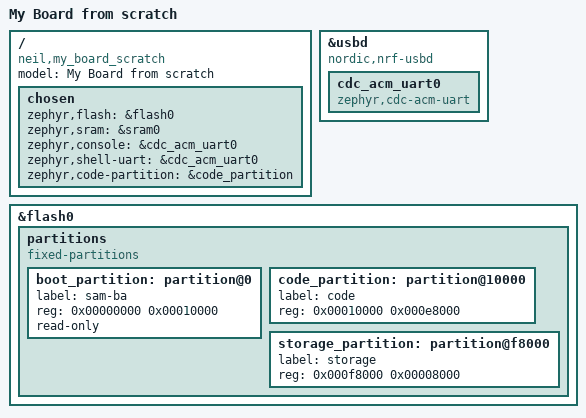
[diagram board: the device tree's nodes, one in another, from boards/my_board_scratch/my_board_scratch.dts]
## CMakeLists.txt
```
# SPDX-License-Identifier: Apache-2.0

cmake_minimum_required(VERSION 3.20.0)
list(APPEND BOARD_ROOT ${CMAKE_CURRENT_SOURCE_DIR})
find_package(Zephyr REQUIRED HINTS $ENV{ZEPHYR_BASE})
project(hello_world_scratch)

target_sources(app PRIVATE src/main.cpp)
```

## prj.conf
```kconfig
#CONFIG_CPP=y
#CONFIG_REQUIRES_FULL_LIBCPP=y
#CONFIG_GPIO=y
#CONFIG_CONSOLE=y
CONFIG_USB_DEVICE_STACK=y
#CONFIG_LOG=y
#CONFIG_PRINTK=y
#CONFIG_BOARD_EARLY_INIT_HOOK=y
CONFIG_USB_DEVICE_INITIALIZE_AT_BOOT=y
#CONFIG_UART_CONSOLE=y
#CONFIG_SERIAL=y
CONFIG_USB_CDC_ACM=y
CONFIG_UART_LINE_CTRL=y
#CONFIG_BOOT_DELAY=2000


## Preparing a separate prj.conf content for L6 onwards
```

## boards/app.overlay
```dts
/* ----practicing with aliases---------------

/{
    aliases{
        my-red-led = &red_led;
    };
};

*/
//--------------------------Homework L4 task 1----------------------------------------------------------

/{
    aliases{
        app-led = &led2; //alias app_led pointing to blue LED, i.e., 
                        // &led2 GPIO0 pin 6 on the nano33 board
    };
};
    
```

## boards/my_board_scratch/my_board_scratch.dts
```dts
/dts-v1/;
#include <nordic/nrf52840_qiaa.dtsi>
//#include <dt-bindings/gpio/gpio.h>
//#include <zephyr/dt-bindings/pinctrl/nrf-pinctrl.h>
/{
    model= "My Board from scratch";
    compatible = "neil,my_board_scratch";

    chosen{
		zephyr,flash = &flash0;
		zephyr,sram = &sram0;
		zephyr,console = &cdc_acm_uart0;
		zephyr,shell-uart = &cdc_acm_uart0;
        zephyr,code-partition = &code_partition;
    };
    
    /*aliases {
		led0 = &led0;
		led1 = &led1;
		led2 = &led2;
		led3 = &led3;
		//led4 = &led4;
	};*/

    //zephyr,user {
	//	/* I2C pull-ups are connected to VDD via pin voltage level */
	//	pull-up-gpios = <&gpio1 0 GPIO_ACTIVE_HIGH>;
	//};
    
    //leds{
    //    compatible = "gpio-leds";
	//    led0: led_0 {
	//        gpios = <&gpio0 24 GPIO_ACTIVE_LOW>;
	//        label = "Red LED";
    //    };

	//    led1: led_1 {
    //	    gpios = <&gpio0 16 GPIO_ACTIVE_LOW>;
	//	    label = "Green LED";
	//    };

	//    led2: led_2 {
	//	    gpios = <&gpio0 6 GPIO_ACTIVE_LOW>;
	//	    label = "Blue LED";
	//    };

	//    led3: led_3 {
	//        /* Cannot be used together with spi2. */
	//	    gpios = <&gpio0 13 GPIO_ACTIVE_HIGH>;
	//	    label = "Yellow LED";
	//    };
    

	    //led4: led_4 {
    	//	gpios = <&gpio1 9 GPIO_ACTIVE_HIGH>;
		//    label = "User LED";
	    //};
    //};
    
};
    
//&gpio0 {
//    status = "okay";
//};

//&gpio1 {
//	status = "okay";
//};

//&gpiote {
//	status = "okay";
//};

   
//zephyr_udc0: &usbd {
&usbd {
    compatible = "nordic,nrf-usbd";
    status = "okay";
    cdc_acm_uart0: cdc_acm_uart0 {
        compatible = "zephyr,cdc-acm-uart";
    };
};
/*
&zephyr_udc0: &usbd {
    cdc_acm_uart0: cdc_acm_uart0 {
        compatible = "zephyr,cdc-acm-uart";
    };
};*/

/*&uart0 {
    compatible = "nordic,nrf-uarte";
    current-speed = <115200>;
    status = "okay";
    pinctrl-0 = <&uart0_default>;
    pinctrl-1 = <&uart0_sleep>;
    pinctrl-names = "default", "sleep";
};
*/
&flash0 {
    partitions {
        compatible = "fixed-partitions";
        #address-cells = <1>;
        #size-cells = <1>;

        boot_partition: partition@0 {
            label = "sam-ba";
            reg = <0x00000000 0x00010000>;
            read-only;
        };

        code_partition: partition@10000 {
            label = "code";
            reg = <0x00010000 0x000e8000>;
        };
       /*
        * The flash starting at 0x000f8000 and ending at
        * 0x000fffff is reserved for use by the application.
        * Storage partition will be used by FCB/LittleFS/NVS
        * if enabled.
        */
        storage_partition: partition@f8000 {
            label = "storage";
            reg = <0x000f8000 0x00008000>;
        };
	};
};
```

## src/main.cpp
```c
/*
 * Copyright (c) 2023, Meta
 *
 * SPDX-License-Identifier: Apache-2.0
 */

#include <zephyr/kernel.h>
//#include <zephyr/usb/usb_device.h>
//#include <zephyr/drivers/uart.h>
int main(void)
{
 
   //const struct device *console = DEVICE_DT_GET(DT_CHOSEN(zephyr_console));
   //if (!device_is_ready(console)) {
    //    return -ENODEV;
    //}  
   //if (usb_enable(NULL) != 0) {
    //  return -1;
   // }

    /* Wait for DTR signal — host serial monitor has connected */
   // uint32_t dtr = 0;
   // while (!dtr) {
    //    uart_line_ctrl_get(console, UART_LINE_CTRL_DTR, &dtr);
    //    k_sleep(K_MSEC(100));
    //}
    printk("--------------- Inside main application loop-----------------------\n");
	printk("Hello, C++ world! Board: %s\t, SoC: %s\n", CONFIG_BOARD, CONFIG_SOC);
    printk("\n---------------End of main application loop--------------");	
	return 0;
}
```
